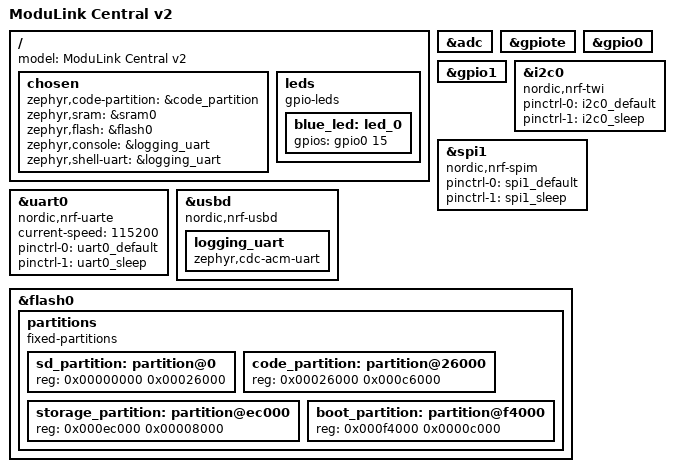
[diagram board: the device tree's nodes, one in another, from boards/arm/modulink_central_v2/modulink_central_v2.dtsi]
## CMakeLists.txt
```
cmake_minimum_required(VERSION 3.20.0)

# allow finding our custom board
set(BOARD_ROOT ${CMAKE_CURRENT_SOURCE_DIR})

find_package(Zephyr REQUIRED HINTS $ENV{ZEPHYR_BASE})

project(modulink)

FILE(GLOB app_sources src/*.c)
target_sources(app PRIVATE ${app_sources} )
```

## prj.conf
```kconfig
CONFIG_GPIO=y

CONFIG_BT=y
# CONFIG_BT_HCI=y
CONFIG_BT_PERIPHERAL=y
CONFIG_BT_DIS=y
CONFIG_BT_SMP=y
CONFIG_BT_BAS=y
# 960 = 0x03C0 meaning "generic HID"
CONFIG_BT_DEVICE_APPEARANCE=962
CONFIG_BT_DEVICE_NAME="ModuLink"
# CONFIG_BT_SETTINGS=y

# https://devzone.nordicsemi.com/f/nordic-q-a/104258/security-failed-level-1-err-9-connecting-error-with-bonded-device/449373
CONFIG_BT_PHY_UPDATE=n

# Increased stack due to settings API usage
CONFIG_SYSTEM_WORKQUEUE_STACK_SIZE=2048

CONFIG_FLASH=y
CONFIG_FLASH_MAP=y
CONFIG_NVS=y
# CONFIG_SETTINGS=y

CONFIG_GPIO=y

# Enable logging
CONFIG_LOG=y
CONFIG_LOG_BACKEND_UART=y
CONFIG_LOG_MODE_IMMEDIATE=y

# Enable console over USB
CONFIG_USB_CDC_ACM=y
CONFIG_SERIAL=y
CONFIG_USB_DEVICE_STACK=y

# Use USB CDC as the console
CONFIG_CONSOLE=y
CONFIG_UART_CONSOLE=y
CONFIG_UART_INTERRUPT_DRIVEN=y
CONFIG_UART_LINE_CTRL=y
```

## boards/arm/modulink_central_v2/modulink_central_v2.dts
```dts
/* copied from https://github.com/zmkfirmware/zmk/blob/main/app/boards/arm/nice_nano/nice_nano_v2.dts */

/dts-v1/;
#include "modulink_central_v2.dtsi"

/ {
    aliases {
        led0 = &blue_led;
    };

    chosen {
        zmk,battery = &vbatt;
    };

    // Node name must match original "EXT_POWER" label to preserve user settings.
    EXT_POWER {
        compatible = "zmk,ext-power-generic";
        control-gpios = <&gpio0 13 GPIO_ACTIVE_HIGH>;
        init-delay-ms = <50>;
    };

    vbatt: vbatt {
        compatible = "zmk,battery-nrf-vddh";
    };
};
```

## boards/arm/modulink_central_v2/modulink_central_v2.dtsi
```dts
/* copied from https://github.com/zmkfirmware/zmk/blob/main/app/boards/arm/nice_nano/nice_nano.dtsi */

/*
 * Copyright (c) 2021 The ZMK Contributors
 *
 * SPDX-License-Identifier: MIT
 */

#include <nordic/nrf52840_qiaa.dtsi>
#include "nice_nano-pinctrl.dtsi"
#include "arduino_pro_micro_pins.dtsi"

/ {
    model = "ModuLink Central v2";

    chosen {
        zephyr,code-partition = &code_partition;
        zephyr,sram = &sram0;
        zephyr,flash = &flash0;
        zephyr,console = &logging_uart;
        zephyr,shell-uart = &logging_uart;
    };

    leds {
        compatible = "gpio-leds";
        blue_led: led_0 {
            gpios = <&gpio0 15 GPIO_ACTIVE_HIGH>;
        };
    };
};

&adc {
    status = "okay";
};

&gpiote {
    status = "okay";
};

&gpio0 {
    status = "okay";
};

&gpio1 {
    status = "okay";
};

&i2c0 {
    compatible = "nordic,nrf-twi";
    pinctrl-0 = <&i2c0_default>;
    pinctrl-1 = <&i2c0_sleep>;
    pinctrl-names = "default", "sleep";
};

&spi1 {
    compatible = "nordic,nrf-spim";
    pinctrl-0 = <&spi1_default>;
    pinctrl-1 = <&spi1_sleep>;
    pinctrl-names = "default", "sleep";
};

&uart0 {
    compatible = "nordic,nrf-uarte";
    current-speed = <115200>;
    pinctrl-0 = <&uart0_default>;
    pinctrl-1 = <&uart0_sleep>;
    pinctrl-names = "default", "sleep";
};

zephyr_udc0: &usbd {
    status = "okay";
    compatible = "nordic,nrf-usbd";
    logging_uart: logging_uart {
        compatible = "zephyr,cdc-acm-uart";
    };
};

&flash0 {
    /*
     * For more information, see:
     * http://docs.zephyrproject.org/latest/devices/dts/flash_partitions.html
     */
    partitions {
        compatible = "fixed-partitions";
        #address-cells = <1>;
        #size-cells = <1>;

        sd_partition: partition@0 {
            reg = <0x00000000 0x00026000>;
        };
        code_partition: partition@26000 {
            reg = <0x00026000 0x000c6000>;
        };

        /*
         * The flash starting at 0x000ec000 and ending at
         * 0x000f3fff is reserved for use by the application.
         */

        /*
         * Storage partition will be used by FCB/LittleFS/NVS
         * if enabled.
         */
        storage_partition: partition@ec000 {
            reg = <0x000ec000 0x00008000>;
        };

        boot_partition: partition@f4000 {
            reg = <0x000f4000 0x0000c000>;
        };
    };
};
```

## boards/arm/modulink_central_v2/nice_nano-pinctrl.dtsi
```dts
/* copied from https://github.com/zmkfirmware/zmk/blob/main/app/boards/arm/nice_nano/nice_nano-pinctrl.dtsi */

/*
 * Copyright (c) 2022 The ZMK Contributors
 * SPDX-License-Identifier: MIT
 */

&pinctrl {
    uart0_default: uart0_default {
        group1 {
            psels = <NRF_PSEL(UART_RX, 0, 8)>;
            bias-pull-up;
        };
        group2 {
            psels = <NRF_PSEL(UART_TX, 0, 6)>;
        };
    };

    uart0_sleep: uart0_sleep {
        group1 {
            psels = <NRF_PSEL(UART_RX, 0, 8)>,
                <NRF_PSEL(UART_TX, 0, 6)>;
            low-power-enable;
        };
    };

    i2c0_default: i2c0_default {
        group1 {
            psels = <NRF_PSEL(TWIM_SDA, 0, 17)>,
                <NRF_PSEL(TWIM_SCL, 0, 20)>;
        };
    };

    i2c0_sleep: i2c0_sleep {
        group1 {
            psels = <NRF_PSEL(TWIM_SDA, 0, 17)>,
                <NRF_PSEL(TWIM_SCL, 0, 20)>;
            low-power-enable;
        };
    };

    spi1_default: spi1_default {
        group1 {
            psels = <NRF_PSEL(SPIM_SCK, 1, 13)>,
                <NRF_PSEL(SPIM_MOSI, 0, 10)>,
                <NRF_PSEL(SPIM_MISO, 1, 11)>;
        };
    };

    spi1_sleep: spi1_sleep {
        group1 {
            psels = <NRF_PSEL(SPIM_SCK, 1, 13)>,
                <NRF_PSEL(SPIM_MOSI, 0, 10)>,
                <NRF_PSEL(SPIM_MISO, 1, 11)>;
            low-power-enable;
        };
    };
};
```

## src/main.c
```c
/*
 * Copyright (c) 2016 Intel Corporation
 *
 * SPDX-License-Identifier: Apache-2.0
 */

#include <stdio.h>
#include <zephyr/kernel.h>
#include <zephyr/drivers/gpio.h>
#include <zephyr/logging/log.h>
#include <zephyr/usb/usb_device.h>
#include "ble.h"
#include "hog.h"

LOG_MODULE_REGISTER(main, LOG_LEVEL_INF);

int main(void) {
	LOG_INF("hello world!");

	int err;

	LOG_INF("initializing BLE");
	err = ble_init();

	LOG_INF("entering hog loop");
	hog_main();

	while (1) {
		LOG_DBG("heartbeat\n");
		k_msleep(1000);
	}
	return 0;
}

int usb_init(void) {
	int usb_enable_ret;

	usb_enable_ret = usb_enable(NULL);

	LOG_INF("USB enabled: %d", usb_enable_ret);

	return 0;
}

SYS_INIT(usb_init, APPLICATION, 50);
```

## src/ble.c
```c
#include <zephyr/types.h>
#include <stddef.h>
#include <string.h>
#include <errno.h>
#include <zephyr/sys/printk.h>
#include <zephyr/sys/byteorder.h>
#include <zephyr/kernel.h>

#include <zephyr/settings/settings.h>

#include <zephyr/bluetooth/bluetooth.h>
#include <zephyr/bluetooth/hci.h>
#include <zephyr/bluetooth/conn.h>
#include <zephyr/bluetooth/uuid.h>
#include <zephyr/bluetooth/gatt.h>
#include <zephyr/logging/log.h>

#include "ble.h"
#include "hog.h"

LOG_MODULE_REGISTER(ble, LOG_LEVEL_DBG);

static const struct bt_data ad[] = {
	BT_DATA_BYTES(BT_DATA_FLAGS, (BT_LE_AD_GENERAL | BT_LE_AD_NO_BREDR)),
	BT_DATA_BYTES(BT_DATA_UUID16_ALL,
			  BT_UUID_16_ENCODE(BT_UUID_HIDS_VAL),
			  BT_UUID_16_ENCODE(BT_UUID_BAS_VAL)),
};

static const struct bt_data sd[] = {
	BT_DATA(BT_DATA_NAME_COMPLETE, CONFIG_BT_DEVICE_NAME, sizeof(CONFIG_BT_DEVICE_NAME) - 1),
};

static void connected(struct bt_conn* conn, uint8_t err) {
	char addr[BT_ADDR_LE_STR_LEN];

	bt_addr_le_to_str(bt_conn_get_dst(conn), addr, sizeof(addr));

	if (err) {
		LOG_ERR("Failed to connect to %s (%u)\n", addr, err);
		return;
	}

	LOG_INF("Connected %s\n", addr);

	if (bt_conn_set_security(conn, BT_SECURITY_L2)) {
		LOG_ERR("Failed to set security\n");
	} else {
		LOG_INF("Security set\n");
	}
}

static void disconnected(struct bt_conn* conn, uint8_t reason) {
	char addr[BT_ADDR_LE_STR_LEN];

	bt_addr_le_to_str(bt_conn_get_dst(conn), addr, sizeof(addr));

	LOG_INF("Disconnected from %s, reason 0x%02x %s\n", addr, reason, bt_hci_err_to_str(reason));
}

static void security_changed(
	struct bt_conn* conn,
	bt_security_t level,
	enum bt_security_err err
) {
	char addr[BT_ADDR_LE_STR_LEN];

	bt_addr_le_to_str(bt_conn_get_dst(conn), addr, sizeof(addr));

	if (!err) {
		LOG_INF("Security changed: %s level %u\n", addr, level);
	} else {
		LOG_ERR("Security failed: %s level %u err %d\n", addr, level, err);
	}
}

BT_CONN_CB_DEFINE(conn_callbacks) = {
	.connected = connected,
	.disconnected = disconnected,
	.security_changed = security_changed,
};

static void bt_ready(int err) {
	if (err) {
		LOG_ERR("Bluetooth init failed (err %d)\n", err);
		return;
	}

	LOG_INF("Bluetooth initialized\n");

	// turned off with CONFIG_SETTINGS commented out
	if (IS_ENABLED(CONFIG_SETTINGS)) {
		LOG_DBG("Loading settings");
		settings_load();
	}

	err = bt_le_adv_start(BT_LE_ADV_CONN_FAST_1, ad, ARRAY_SIZE(ad), sd, ARRAY_SIZE(sd));
	if (err) {
		LOG_ERR("Advertising failed to start (err %d)\n", err);
		return;
	} else {
		LOG_INF("Advertising successfully started\n");
	}
}

int ble_init(void) {
	int err;

	err = bt_enable(bt_ready);
	if (err) {
		LOG_ERR("Bluetooth init failed (err %d)\n", err);
	} else {
		LOG_INF("Bluetooth initialized\n");
	}

	return err;
}
```

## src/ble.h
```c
int ble_init(void);
```

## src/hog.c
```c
/** @file
 *  @brief HoG Service sample
 */

 /*
  * Copyright (c) 2016 Intel Corporation
  *
  * SPDX-License-Identifier: Apache-2.0
  */

#include <zephyr/types.h>
#include <zephyr/drivers/gpio.h>
#include <stddef.h>
#include <string.h>
#include <errno.h>
#include <zephyr/sys/printk.h>
#include <zephyr/sys/byteorder.h>
#include <zephyr/kernel.h>

#include <zephyr/bluetooth/bluetooth.h>
#include <zephyr/bluetooth/hci.h>
#include <zephyr/bluetooth/conn.h>
#include <zephyr/bluetooth/uuid.h>
#include <zephyr/bluetooth/gatt.h>

enum {
	HIDS_REMOTE_WAKE = BIT(0),
	HIDS_NORMALLY_CONNECTABLE = BIT(1),
};

struct hids_info {
	uint16_t version; /* version number of base USB HID Specification */
	uint8_t code; /* country HID Device hardware is localized for. */
	uint8_t flags;
} __packed;

struct hids_report {
	uint8_t id; /* report id */
	uint8_t type; /* report type */
} __packed;

static struct hids_info info = {
	.version = 0x0000,
	.code = 0x00,
	.flags = HIDS_NORMALLY_CONNECTABLE,
};

enum {
	HIDS_INPUT = 0x01,
	HIDS_OUTPUT = 0x02,
	HIDS_FEATURE = 0x03,
};

static struct hids_report input = {
	.id = 0x01,
	.type = HIDS_INPUT,
};

static uint8_t simulate_input;
static uint8_t ctrl_point;
static uint8_t report_map[] = {
	0x05, 0x01, /* Usage Page (Generic Desktop Ctrls) */
	0x09, 0x02, /* Usage (Mouse) */
	0xA1, 0x01, /* Collection (Application) */
	0x85, 0x01, /*	 Report Id (1) */
	0x09, 0x01, /*   Usage (Pointer) */
	0xA1, 0x00, /*   Collection (Physical) */
	0x05, 0x09, /*     Usage Page (Button) */
	0x19, 0x01, /*     Usage Minimum (0x01) */
	0x29, 0x03, /*     Usage Maximum (0x03) */
	0x15, 0x00, /*     Logical Minimum (0) */
	0x25, 0x01, /*     Logical Maximum (1) */
	0x95, 0x03, /*     Report Count (3) */
	0x75, 0x01, /*     Report Size (1) */
	0x81, 0x02, /*     Input (Data,Var,Abs,No Wrap,Linear,...) */
	0x95, 0x01, /*     Report Count (1) */
	0x75, 0x05, /*     Report Size (5) */
	0x81, 0x03, /*     Input (Const,Var,Abs,No Wrap,Linear,...) */
	0x05, 0x01, /*     Usage Page (Generic Desktop Ctrls) */
	0x09, 0x30, /*     Usage (X) */
	0x09, 0x31, /*     Usage (Y) */
	0x15, 0x81, /*     Logical Minimum (129) */
	0x25, 0x7F, /*     Logical Maximum (127) */
	0x75, 0x08, /*     Report Size (8) */
	0x95, 0x02, /*     Report Count (2) */
	0x81, 0x06, /*     Input (Data,Var,Rel,No Wrap,Linear,...) */
	0xC0,       /*   End Collection */
	0xC0,       /* End Collection */
};


static ssize_t read_info(
	struct bt_conn* conn,
	const struct bt_gatt_attr* attr,
	void* buf,
	uint16_t len,
	uint16_t offset
) {
	return bt_gatt_attr_read(conn, attr, buf, len, offset, attr->user_data,
		sizeof(struct hids_info));
}

static ssize_t read_report_map(
	struct bt_conn* conn,
	const struct bt_gatt_attr* attr,
	void* buf,
	uint16_t len,
	uint16_t offset
) {
	return bt_gatt_attr_read(conn, attr, buf, len, offset, report_map,
		sizeof(report_map));
}

static ssize_t read_report(
	struct bt_conn* conn,
	const struct bt_gatt_attr* attr,
	void* buf,
	uint16_t len,
	uint16_t offset
) {
	return bt_gatt_attr_read(conn, attr, buf, len, offset, attr->user_data,
		sizeof(struct hids_report));
}

static void input_ccc_changed(const struct bt_gatt_attr* attr, uint16_t value) {
	simulate_input = (value == BT_GATT_CCC_NOTIFY) ? 1 : 0;
}

static ssize_t read_input_report(struct bt_conn* conn,
	const struct bt_gatt_attr* attr, void* buf,
	uint16_t len, uint16_t offset) {
	return bt_gatt_attr_read(conn, attr, buf, len, offset, NULL, 0);
}

static ssize_t write_ctrl_point(struct bt_conn* conn,
	const struct bt_gatt_attr* attr,
	const void* buf, uint16_t len, uint16_t offset,
	uint8_t flags) {
	uint8_t* value = attr->user_data;

	if (offset + len > sizeof(ctrl_point)) {
		return BT_GATT_ERR(BT_ATT_ERR_INVALID_OFFSET);
	}

	memcpy(value + offset, buf, len);

	return len;
}

#if CONFIG_SAMPLE_BT_USE_AUTHENTICATION
/* Require encryption using authenticated link-key. */
#define SAMPLE_BT_PERM_READ BT_GATT_PERM_READ_AUTHEN
#define SAMPLE_BT_PERM_WRITE BT_GATT_PERM_WRITE_AUTHEN
#else
/* Require encryption. */
#define SAMPLE_BT_PERM_READ BT_GATT_PERM_READ_ENCRYPT
#define SAMPLE_BT_PERM_WRITE BT_GATT_PERM_WRITE_ENCRYPT
#endif

/* HID Service Declaration */
BT_GATT_SERVICE_DEFINE(hog_svc,
	BT_GATT_PRIMARY_SERVICE(BT_UUID_HIDS),
	BT_GATT_CHARACTERISTIC(BT_UUID_HIDS_INFO, BT_GATT_CHRC_READ,
		BT_GATT_PERM_READ, read_info, NULL, &info),
	BT_GATT_CHARACTERISTIC(BT_UUID_HIDS_REPORT_MAP, BT_GATT_CHRC_READ,
		BT_GATT_PERM_READ, read_report_map, NULL, NULL),
	BT_GATT_CHARACTERISTIC(BT_UUID_HIDS_REPORT,
		BT_GATT_CHRC_READ | BT_GATT_CHRC_NOTIFY,
		SAMPLE_BT_PERM_READ,
		read_input_report, NULL, NULL),
	BT_GATT_CCC(input_ccc_changed,
		SAMPLE_BT_PERM_READ | SAMPLE_BT_PERM_WRITE),
	BT_GATT_DESCRIPTOR(BT_UUID_HIDS_REPORT_REF, BT_GATT_PERM_READ,
		read_report, NULL, &input),
	BT_GATT_CHARACTERISTIC(BT_UUID_HIDS_CTRL_POINT,
		BT_GATT_CHRC_WRITE_WITHOUT_RESP,
		BT_GATT_PERM_WRITE,
		NULL, write_ctrl_point, &ctrl_point),
	);

void hog_main(void) {
	for (;;) {
		if (simulate_input) {
			/* HID Report:
			 * Byte 0: buttons (lower 3 bits)
			 * Byte 1: X axis (int8)
			 * Byte 2: Y axis (int8)
			 */
			int8_t report[3] = { 0, 1, 1 };

			// check if button is pressed
			// if (gpio_pin_get_dt(&sw0)) {
			// 	report[0] |= BIT(0);
			// }

			bt_gatt_notify(NULL, &hog_svc.attrs[5],
				report, sizeof(report));
		}
		k_sleep(K_MSEC(100));
	}
}
```

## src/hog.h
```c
void hog_main(void);
```
